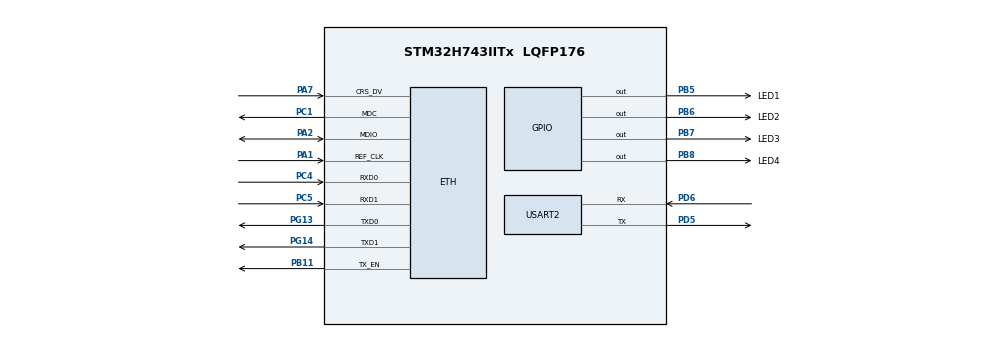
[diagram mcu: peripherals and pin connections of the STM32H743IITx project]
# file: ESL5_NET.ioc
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CORTEX_M7.AccessPermission-Cortex_Memory_Protection_Unit_Region0_Settings=MPU_REGION_FULL_ACCESS
CORTEX_M7.AccessPermission-Cortex_Memory_Protection_Unit_Region1_Settings=MPU_REGION_FULL_ACCESS
CORTEX_M7.BaseAddress-Cortex_Memory_Protection_Unit_Region0_Settings=0x30040000
CORTEX_M7.BaseAddress-Cortex_Memory_Protection_Unit_Region1_Settings=0x30040000
CORTEX_M7.CPU_DCache=Enabled
CORTEX_M7.CPU_ICache=Enabled
CORTEX_M7.Enable-Cortex_Memory_Protection_Unit_Region0_Settings=MPU_REGION_ENABLE
CORTEX_M7.Enable-Cortex_Memory_Protection_Unit_Region1_Settings=MPU_REGION_ENABLE
CORTEX_M7.IsBufferable-Cortex_Memory_Protection_Unit_Region0_Settings=MPU_ACCESS_BUFFERABLE
CORTEX_M7.IsCacheable-Cortex_Memory_Protection_Unit_Region1_Settings=MPU_ACCESS_CACHEABLE
CORTEX_M7.MPU_Control=MPU_PRIVILEGED_DEFAULT
CORTEX_M7.Size-Cortex_Memory_Protection_Unit_Region0_Settings=MPU_REGION_SIZE_256B
CORTEX_M7.Size-Cortex_Memory_Protection_Unit_Region1_Settings=MPU_REGION_SIZE_16KB
ETH.MediaInterface=HAL_ETH_RMII_MODE
FREERTOS.Mutexes01=myKey,Static,myKeyControlBlock
FREERTOS.Tasks01=defaultTask,0,128,StartDefaultTask,Default,NULL,Dynamic,NULL,NULL;myTaskLED,-3,128,StartTaskLED,Default,NULL,Dynamic,NULL,NULL
FREERTOS.configUSE_PREEMPTION=1
FREERTOS.configUSE_TRACE_FACILITY=1
LWIP.BSP.number=1
LWIP.GATEWAY_ADDRESS=192.168.031.001
LWIP.IP_ADDRESS=192.168.031.024
LWIP.LWIP_DHCP=0
LWIP.NETMASK_ADDRESS=255.255.255.000
LWIP.Version=v2.1.2_Cube
LWIP0.BSP.STBoard=false
LWIP0.BSP.api=BSP_COMPONENT_DRIVER
LWIP0.BSP.component=LAN8742
LWIP0.BSP.i2caddr=0
LWIP0.BSP.instance=LAN8742
LWIP0.BSP.name=Driver_PHY
LWIP0.BSP.solution=LAN8742
Mcu.Family=STM32H7
Mcu.Name=STM32H743IITx
Mcu.Package=LQFP176
NVIC.ETH_IRQn=true\:5\:0\:false\:false\:true\:true\:true\:true
NVIC.PriorityGroup=NVIC_PRIORITYGROUP_4
NVIC.TIM1_BRK_IRQn=true\:5\:0\:false\:false\:true\:true\:true\:true
NVIC.TIM2_IRQn=true\:15\:0\:false\:false\:true\:false\:false\:true
NVIC.TimeBase=TIM2_IRQn
NVIC.TimeBaseIP=TIM2
NVIC.USART2_IRQn=true\:5\:0\:false\:false\:true\:true\:true\:true
PA1.GPIO_Speed=GPIO_SPEED_FREQ_VERY_HIGH
PA1.Mode=RMII
PA1.Signal=ETH_REF_CLK
PA13\ (JTMS/SWDIO).Mode=Trace_Asynchronous_SW
PA13\ (JTMS/SWDIO).Signal=DEBUG_JTMS-SWDIO
PA14\ (JTCK/SWCLK).Mode=Trace_Asynchronous_SW
PA14\ (JTCK/SWCLK).Signal=DEBUG_JTCK-SWCLK
PA2.GPIO_Speed=GPIO_SPEED_FREQ_VERY_HIGH
PA2.Mode=RMII
PA2.Signal=ETH_MDIO
PA7.GPIO_Speed=GPIO_SPEED_FREQ_VERY_HIGH
PA7.Mode=RMII
PA7.Signal=ETH_CRS_DV
PB11.GPIO_Speed=GPIO_SPEED_FREQ_VERY_HIGH
PB11.Mode=RMII
PB11.Signal=ETH_TX_EN
PB3\ (JTDO/TRACESWO).Mode=Trace_Asynchronous_SW
PB3\ (JTDO/TRACESWO).Signal=DEBUG_JTDO-SWO
PB5.GPIO_Label=LED1
PB5.Signal=GPIO_Output
PB6.GPIO_Label=LED2
PB6.Signal=GPIO_Output
PB7.GPIO_Label=LED3
PB7.Signal=GPIO_Output
PB8.GPIO_Label=LED4
PB8.Signal=GPIO_Output
PC1.GPIO_Speed=GPIO_SPEED_FREQ_VERY_HIGH
PC1.Mode=RMII
PC1.Signal=ETH_MDC
PC4.GPIO_Speed=GPIO_SPEED_FREQ_VERY_HIGH
PC4.Mode=RMII
PC4.Signal=ETH_RXD0
PC5.GPIO_Speed=GPIO_SPEED_FREQ_VERY_HIGH
PC5.Mode=RMII
PC5.Signal=ETH_RXD1
PD5.Mode=Asynchronous
PD5.Signal=USART2_TX
PD6.Mode=Asynchronous
PD6.Signal=USART2_RX
PG13.GPIO_Speed=GPIO_SPEED_FREQ_VERY_HIGH
PG13.Mode=RMII
PG13.Signal=ETH_TXD0
PG14.GPIO_Speed=GPIO_SPEED_FREQ_VERY_HIGH
PG14.Mode=RMII
PG14.Signal=ETH_TXD1
PH0-OSC_IN\ (PH0).Mode=HSE-External-Oscillator
PH0-OSC_IN\ (PH0).Signal=RCC_OSC_IN
PH1-OSC_OUT\ (PH1).Mode=HSE-External-Oscillator
PH1-OSC_OUT\ (PH1).Signal=RCC_OSC_OUT
ProjectManager.HeapSize=0x200
ProjectManager.StackSize=0x400
ProjectManager.TargetToolchain=MDK-ARM V5
RCC.ADCFreq_Value=50390625
RCC.APB1Freq_Value=100000000
RCC.APB2Freq_Value=100000000
RCC.APB3Freq_Value=100000000
RCC.APB4Freq_Value=100000000
RCC.CortexFreq_Value=400000000
RCC.D1PPRE=RCC_APB3_DIV2
RCC.D2PPRE1=RCC_APB1_DIV2
RCC.D2PPRE2=RCC_APB2_DIV2
RCC.D3PPRE=RCC_APB4_DIV2
RCC.DIVM1=5
RCC.DIVN1=160
RCC.HCLKFreq_Value=200000000
RCC.HPRE=RCC_HCLK_DIV2
RCC.PLL2FRACN=0
RCC.PLL3FRACN=0
RCC.PLLFRACN=0
RCC.PLLSourceVirtual=RCC_PLLSOURCE_HSE
RCC.PWR_Regulator_Voltage_Scale=PWR_REGULATOR_VOLTAGE_SCALE0
RCC.SYSCLKFreq_VALUE=400000000
RCC.SYSCLKSource=RCC_SYSCLKSOURCE_PLLCLK
RCC.SupplySource=PWR_LDO_SUPPLY
RCC.USBFreq_Value=400000000
USART2.RxPinLevelInvertParam=ADVFEATURE_RXINV_DISABLE
USART2.TxPinLevelInvertParam=ADVFEATURE_TXINV_DISABLE
USART2.VirtualMode-Asynchronous=VM_ASYNC
VP_FREERTOS_VS_CMSIS_V1.Mode=CMSIS_V1
VP_LWIP_VS_Enabled.Mode=Enabled
VP_SYS_VS_tim2.Mode=TIM2
VP_TIM1_VS_ClockSourceINT.Mode=Internal
VP_TIM1_VS_ClockSourceITR.Mode=TriggerSource_ITR1
VP_TIM1_VS_ControllerModeTrigger.Mode=Trigger Mode
board=custom

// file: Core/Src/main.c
/* USER CODE BEGIN Header */
/**
  ******************************************************************************
  * @file           : main.c
  * @brief          : Main program body
  ******************************************************************************
  * @attention
  *
  * <h2><center>&copy; Copyright (c) 2023 STMicroelectronics.
  * All rights reserved.</center></h2>
  *
  * This software component is licensed by ST under Ultimate Liberty license
  * SLA0044, the "License"; You may not use this file except in compliance with
  * the License. You may obtain a copy of the License at:
  *                             www.st.com/SLA0044
  *
  ******************************************************************************
  */
/* USER CODE END Header */
#include "main.h"
#include "cmsis_os.h"
#include "lwip.h"
#include "tim.h"
#include "usart.h"
#include "gpio.h"

/* USER CODE BEGIN PM */
extern void uart_event(void);
extern UART_HandleTypeDef UART2_Handler; //UART���
/* USER CODE END PM */

void SystemClock_Config(void);
static void MPU_Config(void);
void MX_FREERTOS_Init(void);

int main(void)
{

  /* MPU Configuration--------------------------------------------------------*/
  MPU_Config();

  /* Enable I-Cache---------------------------------------------------------*/
  SCB_EnableICache();

  /* Enable D-Cache---------------------------------------------------------*/
  SCB_EnableDCache();

  /* MCU Configuration--------------------------------------------------------*/

  /* Reset of all peripherals, Initializes the Flash interface and the Systick. */
  HAL_Init();

  /* Configure the system clock */
  SystemClock_Config();
  osDelay(100);

  /* Initialize all configured peripherals */
  MX_GPIO_Init();
  MX_TIM1_Init();
  MX_USART2_UART_Init();

  /* Call init function for freertos objects (in freertos.c) */
  MX_FREERTOS_Init();
  /* Start scheduler */
  osKernelStart();

  /* We should never get here as control is now taken by the scheduler */
  /* Infinite loop */
  while (1)
  {

  }
}

void SystemClock_Config(void)
{
  RCC_OscInitTypeDef RCC_OscInitStruct = {0};
  RCC_ClkInitTypeDef RCC_ClkInitStruct = {0};

  /** Supply configuration update enable
  */
  HAL_PWREx_ConfigSupply(PWR_LDO_SUPPLY);
  /** Configure the main internal regulator output voltage
  */
  __HAL_PWR_VOLTAGESCALING_CONFIG(PWR_REGULATOR_VOLTAGE_SCALE0);

  while(!__HAL_PWR_GET_FLAG(PWR_FLAG_VOSRDY)) {}
  /** Initializes the RCC Oscillators according to the specified parameters
  * in the RCC_OscInitTypeDef structure.
  */
  RCC_OscInitStruct.OscillatorType = RCC_OSCILLATORTYPE_HSE;
  RCC_OscInitStruct.HSEState = RCC_HSE_ON;
  RCC_OscInitStruct.PLL.PLLState = RCC_PLL_ON;
  RCC_OscInitStruct.PLL.PLLSource = RCC_PLLSOURCE_HSE;
  RCC_OscInitStruct.PLL.PLLM = 5;
  RCC_OscInitStruct.PLL.PLLN = 160;
  RCC_OscInitStruct.PLL.PLLP = 2;
  RCC_OscInitStruct.PLL.PLLQ = 2;
  RCC_OscInitStruct.PLL.PLLR = 2;
  RCC_OscInitStruct.PLL.PLLRGE = RCC_PLL1VCIRANGE_2;
  RCC_OscInitStruct.PLL.PLLVCOSEL = RCC_PLL1VCOWIDE;
  RCC_OscInitStruct.PLL.PLLFRACN = 0;
  if (HAL_RCC_OscConfig(&RCC_OscInitStruct) != HAL_OK)
  {
    Error_Handler();
  }
  /** Initializes the CPU, AHB and APB buses clocks
  */
  RCC_ClkInitStruct.ClockType = RCC_CLOCKTYPE_HCLK|RCC_CLOCKTYPE_SYSCLK
                              |RCC_CLOCKTYPE_PCLK1|RCC_CLOCKTYPE_PCLK2
                              |RCC_CLOCKTYPE_D3PCLK1|RCC_CLOCKTYPE_D1PCLK1;
  RCC_ClkInitStruct.SYSCLKSource = RCC_SYSCLKSOURCE_PLLCLK;
  RCC_ClkInitStruct.SYSCLKDivider = RCC_SYSCLK_DIV1;
  RCC_ClkInitStruct.AHBCLKDivider = RCC_HCLK_DIV2;
  RCC_ClkInitStruct.APB3CLKDivider = RCC_APB3_DIV2;
  RCC_ClkInitStruct.APB1CLKDivider = RCC_APB1_DIV2;
  RCC_ClkInitStruct.APB2CLKDivider = RCC_APB2_DIV2;
  RCC_ClkInitStruct.APB4CLKDivider = RCC_APB4_DIV2;

  if (HAL_RCC_ClockConfig(&RCC_ClkInitStruct, FLASH_LATENCY_2) != HAL_OK)
  {
    Error_Handler();
  }
}

/* MPU Configuration */

void MPU_Config(void)
{
  MPU_Region_InitTypeDef MPU_InitStruct = {0};

  /* Disables the MPU */
  HAL_MPU_Disable();
  /** Initializes and configures the Region and the memory to be protected
  */
  MPU_InitStruct.Enable = MPU_REGION_ENABLE;
  MPU_InitStruct.Number = MPU_REGION_NUMBER0;
  MPU_InitStruct.BaseAddress = 0x30040000;
  MPU_InitStruct.Size = MPU_REGION_SIZE_256B;
  MPU_InitStruct.SubRegionDisable = 0x0;
  MPU_InitStruct.TypeExtField = MPU_TEX_LEVEL0;
  MPU_InitStruct.AccessPermission = MPU_REGION_FULL_ACCESS;
  MPU_InitStruct.DisableExec = MPU_INSTRUCTION_ACCESS_ENABLE;
  MPU_InitStruct.IsShareable = MPU_ACCESS_NOT_SHAREABLE;
  MPU_InitStruct.IsCacheable = MPU_ACCESS_NOT_CACHEABLE;
  MPU_InitStruct.IsBufferable = MPU_ACCESS_BUFFERABLE;

  HAL_MPU_ConfigRegion(&MPU_InitStruct);
  /** Initializes and configures the Region and the memory to be protected
  */
  MPU_InitStruct.Number = MPU_REGION_NUMBER1;
  MPU_InitStruct.Size = MPU_REGION_SIZE_16KB;
  MPU_InitStruct.IsCacheable = MPU_ACCESS_CACHEABLE;
  MPU_InitStruct.IsBufferable = MPU_ACCESS_NOT_BUFFERABLE;

  HAL_MPU_ConfigRegion(&MPU_InitStruct);
  /* Enables the MPU */
  HAL_MPU_Enable(MPU_PRIVILEGED_DEFAULT);

}

void HAL_TIM_PeriodElapsedCallback(TIM_HandleTypeDef *htim)
{
  if (htim->Instance == TIM2) {
    HAL_IncTick();
  }
}

void Error_Handler(void)
{
  __disable_irq();
  while (1)
  {
  }
}

/************************ (C) COPYRIGHT STMicroelectronics *****END OF FILE****/

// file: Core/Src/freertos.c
/* USER CODE BEGIN Header */
/**
  ******************************************************************************
  * File Name          : freertos.c
  * Description        : Code for freertos applications
  ******************************************************************************
  * @attention
  *
  * <h2><center>&copy; Copyright (c) 2023 STMicroelectronics.
  * All rights reserved.</center></h2>
  *
  * This software component is licensed by ST under Ultimate Liberty license
  * SLA0044, the "License"; You may not use this file except in compliance with
  * the License. You may obtain a copy of the License at:
  *                             www.st.com/SLA0044
  *
  ******************************************************************************
  */
/* USER CODE END Header */

#include "FreeRTOS.h"
#include "task.h"
#include "main.h"
#include "cmsis_os.h"

osThreadId defaultTaskHandle;
osThreadId myTaskLEDHandle;
osMutexId myKeyHandle;
osStaticMutexDef_t myKeyControlBlock;

void StartDefaultTask(void const * argument);
void StartTaskLED(void const * argument);

extern void MX_LWIP_Init(void);
void MX_FREERTOS_Init(void); /* (MISRA C 2004 rule 8.1) */

/* GetIdleTaskMemory prototype (linked to static allocation support) */
void vApplicationGetIdleTaskMemory( StaticTask_t **ppxIdleTaskTCBBuffer, StackType_t **ppxIdleTaskStackBuffer, uint32_t *pulIdleTaskStackSize );

/* USER CODE BEGIN GET_IDLE_TASK_MEMORY */
static StaticTask_t xIdleTaskTCBBuffer;
static StackType_t xIdleStack[configMINIMAL_STACK_SIZE];

void vApplicationGetIdleTaskMemory( StaticTask_t **ppxIdleTaskTCBBuffer, StackType_t **ppxIdleTaskStackBuffer, uint32_t *pulIdleTaskStackSize )
{
  *ppxIdleTaskTCBBuffer = &xIdleTaskTCBBuffer;
  *ppxIdleTaskStackBuffer = &xIdleStack[0];
  *pulIdleTaskStackSize = configMINIMAL_STACK_SIZE;
  /* place for user code */
}
/* USER CODE END GET_IDLE_TASK_MEMORY */

void MX_FREERTOS_Init(void) {
  /* Create the mutex(es) */
  /* definition and creation of myKey */
  osMutexStaticDef(myKey, &myKeyControlBlock);
  myKeyHandle = osMutexCreate(osMutex(myKey));

  /* Create the thread(s) */
  /* definition and creation of defaultTask */
  osThreadDef(defaultTask, StartDefaultTask, osPriorityNormal, 0, 128);
  defaultTaskHandle = osThreadCreate(osThread(defaultTask), NULL);

  /* definition and creation of myTaskLED */
  osThreadDef(myTaskLED, StartTaskLED, osPriorityIdle, 0, 128);
  myTaskLEDHandle = osThreadCreate(osThread(myTaskLED), NULL);

}

void StartDefaultTask(void const * argument)
{
  /* init code for LWIP */
  MX_LWIP_Init();
  /* USER CODE BEGIN StartDefaultTask */
  /* Infinite loop */
  for(;;)
  {
	MX_LWIP_Process();
	HAL_GPIO_TogglePin(GPIOB,LED2_Pin);
	printf("Led2 flash\r\n");
	osDelay(500);
  }
  /* USER CODE END StartDefaultTask */
}

void StartTaskLED(void const * argument)
{
  /* USER CODE BEGIN StartTaskLED */
  /* Infinite loop */
  for(;;)
  {
		HAL_GPIO_TogglePin(GPIOB,LED1_Pin);
		printf("Led1 flash\r\n");
		osDelay(1000);
  }
  /* USER CODE END StartTaskLED */
}

/************************ (C) COPYRIGHT STMicroelectronics *****END OF FILE****/
